# USB_USB2SS_PHY2_0F908000h register map
Vendor: Texas Instruments
Peripheral module from a debugger description file (folder AM275x).
Registers are 32-bit, read-write, reset 0x0 unless marked. A register's access mark holds for its fields unless they carry their own. Offsets are as the file gives them; lines under a group give offsets from that group; [hi:lo] are bit positions; {n}, {i} and the like mark numbered series; 'fields as' and 'values as' point back to an identical list; <NAME> marks a mode.

## usb2ss_phy2 (part 1 of 3)
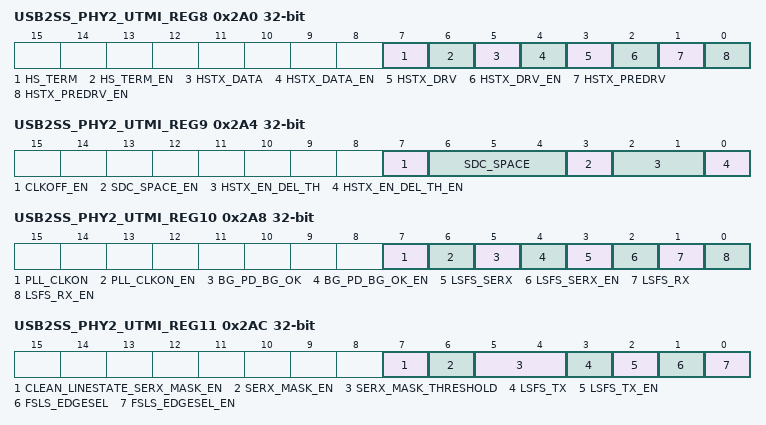
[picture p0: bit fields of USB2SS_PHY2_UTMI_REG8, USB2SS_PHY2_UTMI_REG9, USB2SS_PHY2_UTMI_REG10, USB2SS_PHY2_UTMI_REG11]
0x2A0 USB2SS_PHY2_UTMI_REG8 — This is a reserved register or field. It should not be written or read, and the value should be ignored.
  [7] HS_TERM — This is a reserved register or field. It should not be written or read, and the value should be ignored. Reset Source: usb2_sync_preset_n
  [6] HS_TERM_EN — This is a reserved register or field. It should not be written or read, and the value should be ignored. Reset Source: usb2_sync_preset_n
  [5] HSTX_DATA — This is a reserved register or field. It should not be written or read, and the value should be ignored. Reset Source: usb2_sync_preset_n
  [4] HSTX_DATA_EN — This is a reserved register or field. It should not be written or read, and the value should be ignored. Reset Source: usb2_sync_preset_n
  [3] HSTX_DRV — This is a reserved register or field. It should not be written or read, and the value should be ignored. Reset Source: usb2_sync_preset_n
  [2] HSTX_DRV_EN — This is a reserved register or field. It should not be written or read, and the value should be ignored. Reset Source: usb2_sync_preset_n
  [1] HSTX_PREDRV — This is a reserved register or field. It should not be written or read, and the value should be ignored. Reset Source: usb2_sync_preset_n
  [0] HSTX_PREDRV_EN — This is a reserved register or field. It should not be written or read, and the value should be ignored. Reset Source: usb2_sync_preset_n
0x2A4 USB2SS_PHY2_UTMI_REG9 — hs delay values
  [7] CLKOFF_EN — This is a reserved register or field. It should not be written or read, and the value should be ignored. Reset Source: usb2_sync_preset_n
  [6:4] SDC_SPACE — 000- The time between successive resistor calibration is 0ms, 001- The time between successive resistor calibration is 500ms, 010- The time between successive resistor calibration is 1000ms, 011- The time between successive resistor calibration is1500ms, 100- The time between successive resistor calibration is 2000ms, 101- The time between successive resistor calibration is 2500ms, 110- The time between successive resistor calibration is 3000ms, 111- The time between successive resistor calibration is 3500ms. Reset Source: usb2_sync_preset_n
  [3] SDC_SPACE_EN — 0- The time between successive resistor calibration taken as 1s by default, 1- The time between successive resistor calibration taken from UTMI_REG9[6:4]. Reset Source: usb2_sync_preset_n
  [2:1] HSTX_EN_DEL_TH — This is a reserved register or field. It should not be written or read, and the value should be ignored. Reset Source: usb2_sync_preset_n
  [0] HSTX_EN_DEL_TH_EN — This is a reserved register or field. It should not be written or read, and the value should be ignored. Reset Source: usb2_sync_preset_n
0x2A8 USB2SS_PHY2_UTMI_REG10 — This is a reserved register or field. It should not be written or read, and the value should be ignored.
  [7] PLL_CLKON — This is a reserved register or field. It should not be written or read, and the value should be ignored. Reset Source: usb2_sync_preset_n
  [6] PLL_CLKON_EN — This is a reserved register or field. It should not be written or read, and the value should be ignored. Reset Source: usb2_sync_preset_n
  [5] BG_PD_BG_OK — This is a reserved register or field. It should not be written or read, and the value should be ignored. Reset Source: usb2_sync_preset_n
  [4] BG_PD_BG_OK_EN — This is a reserved register or field. It should not be written or read, and the value should be ignored. Reset Source: usb2_sync_preset_n
  [3] LSFS_SERX — This is a reserved register or field. It should not be written or read, and the value should be ignored. Reset Source: usb2_sync_preset_n
  [2] LSFS_SERX_EN — This is a reserved register or field. It should not be written or read, and the value should be ignored. Reset Source: usb2_sync_preset_n
  [1] LSFS_RX — This is a reserved register or field. It should not be written or read, and the value should be ignored. Reset Source: usb2_sync_preset_n
  [0] LSFS_RX_EN — This is a reserved register or field. It should not be written or read, and the value should be ignored. Reset Source: usb2_sync_preset_n
0x2AC USB2SS_PHY2_UTMI_REG11 — This is a reserved register or field. It should not be written or read, and the value should be ignored.
  [7] CLEAN_LINESTATE_SERX_MASK_EN — This is a reserved register or field. It should not be written or read, and the value should be ignored. Reset Source: usb2_sync_preset_n
  [6] SERX_MASK_EN — This is a reserved register or field. It should not be written or read, and the value should be ignored. Reset Source: usb2_sync_preset_n
  [5:4] SERX_MASK_THRESHOLD — This is a reserved register or field. It should not be written or read, and the value should be ignored. Reset Source: usb2_sync_preset_n
  [3] LSFS_TX — This is a reserved register or field. It should not be written or read, and the value should be ignored. Reset Source: usb2_sync_preset_n
  [2] LSFS_TX_EN — This is a reserved register or field. It should not be written or read, and the value should be ignored. Reset Source: usb2_sync_preset_n
  [1] FSLS_EDGESEL — This is a reserved register or field. It should not be written or read, and the value should be ignored. Reset Source: usb2_sync_preset_n
  [0] FSLS_EDGESEL_EN — This is a reserved register or field. It should not be written or read, and the value should be ignored. Reset Source: usb2_sync_preset_n
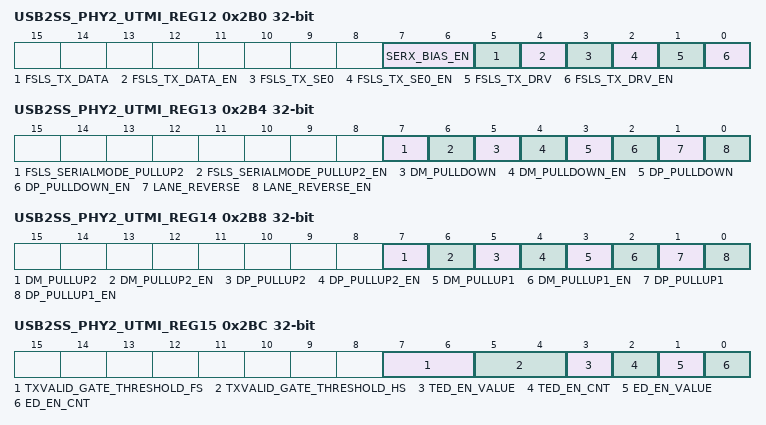
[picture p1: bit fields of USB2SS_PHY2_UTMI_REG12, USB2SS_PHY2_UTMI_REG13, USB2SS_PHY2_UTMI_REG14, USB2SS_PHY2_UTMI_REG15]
0x2B0 USB2SS_PHY2_UTMI_REG12 — This is a reserved register or field. It should not be written or read, and the value should be ignored.
  [7:6] SERX_BIAS_EN — This is a reserved register or field. It should not be written or read, and the value should be ignored. Reset Source: usb2_sync_preset_n
  [5] FSLS_TX_DATA — This is a reserved register or field. It should not be written or read, and the value should be ignored. Reset Source: usb2_sync_preset_n
  [4] FSLS_TX_DATA_EN — This is a reserved register or field. It should not be written or read, and the value should be ignored. Reset Source: usb2_sync_preset_n
  [3] FSLS_TX_SE0 — This is a reserved register or field. It should not be written or read, and the value should be ignored. Reset Source: usb2_sync_preset_n
  [2] FSLS_TX_SE0_EN — This is a reserved register or field. It should not be written or read, and the value should be ignored. Reset Source: usb2_sync_preset_n
  [1] FSLS_TX_DRV — This is a reserved register or field. It should not be written or read, and the value should be ignored. Reset Source: usb2_sync_preset_n
  [0] FSLS_TX_DRV_EN — This is a reserved register or field. It should not be written or read, and the value should be ignored. Reset Source: usb2_sync_preset_n
0x2B4 USB2SS_PHY2_UTMI_REG13 — serial mode
  [7] FSLS_SERIALMODE_PULLUP2 — This is a reserved register or field. It should not be written or read, and the value should be ignored. Reset Source: usb2_sync_preset_n
  [6] FSLS_SERIALMODE_PULLUP2_EN — This is a reserved register or field. It should not be written or read, and the value should be ignored. Reset Source: usb2_sync_preset_n
  [5] DM_PULLDOWN — This is a reserved register or field. It should not be written or read, and the value should be ignored. Reset Source: usb2_sync_preset_n
  [4] DM_PULLDOWN_EN — This is a reserved register or field. It should not be written or read, and the value should be ignored. Reset Source: usb2_sync_preset_n
  [3] DP_PULLDOWN — This is a reserved register or field. It should not be written or read, and the value should be ignored. Reset Source: usb2_sync_preset_n
  [2] DP_PULLDOWN_EN — This is a reserved register or field. It should not be written or read, and the value should be ignored. Reset Source: usb2_sync_preset_n
  [1] LANE_REVERSE — 0- Polarity inversion of DP/DM is not done, 1- Polarity inversion of DP/DM is done Reset Source: usb2_sync_preset_n
  [0] LANE_REVERSE_EN — 0- Lane Reverse Value is taken from primary input portlane_reverse, 1- Lane Reverse Value taken from UTMI_REG13[1] Reset Source: usb2_sync_preset_n
0x2B8 USB2SS_PHY2_UTMI_REG14 — This is a reserved register or field. It should not be written or read, and the value should be ignored.
  [7] DM_PULLUP2 — This is a reserved register or field. It should not be written or read, and the value should be ignored. Reset Source: usb2_sync_preset_n
  [6] DM_PULLUP2_EN — This is a reserved register or field. It should not be written or read, and the value should be ignored. Reset Source: usb2_sync_preset_n
  [5] DP_PULLUP2 — This is a reserved register or field. It should not be written or read, and the value should be ignored. Reset Source: usb2_sync_preset_n
  [4] DP_PULLUP2_EN — This is a reserved register or field. It should not be written or read, and the value should be ignored. Reset Source: usb2_sync_preset_n
  [3] DM_PULLUP1 — This is a reserved register or field. It should not be written or read, and the value should be ignored. Reset Source: usb2_sync_preset_n
  [2] DM_PULLUP1_EN — This is a reserved register or field. It should not be written or read, and the value should be ignored. Reset Source: usb2_sync_preset_n
  [1] DP_PULLUP1 — This is a reserved register or field. It should not be written or read, and the value should be ignored. Reset Source: usb2_sync_preset_n
  [0] DP_PULLUP1_EN — This is a reserved register or field. It should not be written or read, and the value should be ignored. Reset Source: usb2_sync_preset_n
0x2BC USB2SS_PHY2_UTMI_REG15 — This is a reserved register or field. It should not be written or read, and the value should be ignored.
  [7:6] TXVALID_GATE_THRESHOLD_FS — This is a reserved register or field. It should not be written or read, and the value should be ignored. Reset Source: usb2_sync_preset_n
  [5:4] TXVALID_GATE_THRESHOLD_HS — This is a reserved register or field. It should not be written or read, and the value should be ignored. Reset Source: usb2_sync_preset_n
  [3] TED_EN_VALUE — This is a reserved register or field. It should not be written or read, and the value should be ignored. Reset Source: usb2_sync_preset_n
  [2] TED_EN_CNT — This is a reserved register or field. It should not be written or read, and the value should be ignored. Reset Source: usb2_sync_preset_n
  [1] ED_EN_VALUE — This is a reserved register or field. It should not be written or read, and the value should be ignored. Reset Source: usb2_sync_preset_n
  [0] ED_EN_CNT — This is a reserved register or field. It should not be written or read, and the value should be ignored. Reset Source: usb2_sync_preset_n
0x2C0 USB2SS_PHY2_UTMI_REG16 (reset mask 0xFF) — This is a reserved register or field. It should not be written or read, and the value should be ignored.
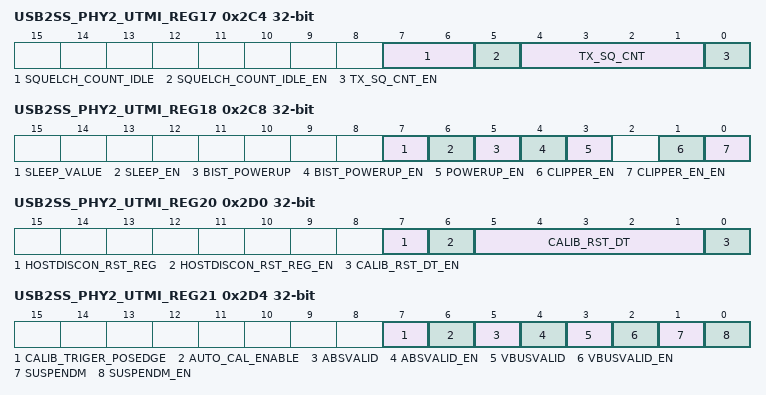
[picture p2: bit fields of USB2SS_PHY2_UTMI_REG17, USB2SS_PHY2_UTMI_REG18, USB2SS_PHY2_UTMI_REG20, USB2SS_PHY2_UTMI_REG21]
0x2C4 USB2SS_PHY2_UTMI_REG17 — This is a reserved register or field. It should not be written or read, and the value should be ignored.
  [7:6] SQUELCH_COUNT_IDLE — This is a reserved register or field. It should not be written or read, and the value should be ignored. Reset Source: usb2_sync_preset_n
  [5] SQUELCH_COUNT_IDLE_EN — This is a reserved register or field. It should not be written or read, and the value should be ignored. Reset Source: usb2_sync_preset_n
  [4:1] TX_SQ_CNT — This is a reserved register or field. It should not be written or read, and the value should be ignored. Reset Source: usb2_sync_preset_n
  [0] TX_SQ_CNT_EN — This is a reserved register or field. It should not be written or read, and the value should be ignored. Reset Source: usb2_sync_preset_n
0x2C8 USB2SS_PHY2_UTMI_REG18 — This is a reserved register or field. It should not be written or read, and the value should be ignored.
  [7] SLEEP_VALUE — This is a reserved register or field. It should not be written or read, and the value should be ignored. Reset Source: usb2_sync_preset_n
  [6] SLEEP_EN — This is a reserved register or field. It should not be written or read, and the value should be ignored. Reset Source: usb2_sync_preset_n
  [5] BIST_POWERUP — This is a reserved register or field. It should not be written or read, and the value should be ignored. Reset Source: usb2_sync_preset_n
  [4] BIST_POWERUP_EN — This is a reserved register or field. It should not be written or read, and the value should be ignored. Reset Source: usb2_sync_preset_n
  [3] POWERUP_EN — This is a reserved register or field. It should not be written or read, and the value should be ignored. Reset Source: usb2_sync_preset_n
  [1] CLIPPER_EN — This is a reserved register or field. It should not be written or read, and the value should be ignored. Reset Source: usb2_sync_preset_n
  [0] CLIPPER_EN_EN — This is a reserved register or field. It should not be written or read, and the value should be ignored. Reset Source: usb2_sync_preset_n
0x2CC USB2SS_PHY2_UTMI_REG19 — This is a reserved register or field. It should not be written or read, and the value should be ignored.
  [0] TED_SW_EN — This is a reserved register or field. It should not be written or read, and the value should be ignored. Reset Source: usb2_sync_preset_n
0x2D0 USB2SS_PHY2_UTMI_REG20 — This is a reserved register or field. It should not be written or read, and the value should be ignored.
  [7] HOSTDISCON_RST_REG — This is a reserved register or field. It should not be written or read, and the value should be ignored. Reset Source: usb2_sync_preset_n
  [6] HOSTDISCON_RST_REG_EN — This is a reserved register or field. It should not be written or read, and the value should be ignored. Reset Source: usb2_sync_preset_n
  [5:1] CALIB_RST_DT — This is a reserved register or field. It should not be written or read, and the value should be ignored. Reset Source: usb2_sync_preset_n
  [0] CALIB_RST_DT_EN — This is a reserved register or field. It should not be written or read, and the value should be ignored. Reset Source: usb2_sync_preset_n
0x2D4 USB2SS_PHY2_UTMI_REG21 — Register UTMI_REG21
  [7] CALIB_TRIGER_POSEDGE — This is a reserved register or field. It should not be written or read, and the value should be ignored. Reset Source: usb2_sync_preset_n
  [6] AUTO_CAL_ENABLE — 0- Dynamic resistor calibration is disabled, 1- Dynamic resistor calibration is enabled Reset Source: usb2_sync_preset_n
  [5] ABSVALID — This is a reserved register or field. It should not be written or read, and the value should be ignored. Reset Source: usb2_sync_preset_n
  [4] ABSVALID_EN — This is a reserved register or field. It should not be written or read, and the value should be ignored. Reset Source: usb2_sync_preset_n
  [3] VBUSVALID — This is a reserved register or field. It should not be written or read, and the value should be ignored. Reset Source: usb2_sync_preset_n
  [2] VBUSVALID_EN — This is a reserved register or field. It should not be written or read, and the value should be ignored. Reset Source: usb2_sync_preset_n
  [1] SUSPENDM — This is a reserved register or field. It should not be written or read, and the value should be ignored. Reset Source: usb2_sync_preset_n
  [0] SUSPENDM_EN — This is a reserved register or field. It should not be written or read, and the value should be ignored. Reset Source: usb2_sync_preset_n
0x2D8 USB2SS_PHY2_UTMI_REG22 — This is a reserved register or field. It should not be written or read, and the value should be ignored.
  [7:0] BCCALIB_OFFSET — This is a reserved register or field. It should not be written or read, and the value should be ignored. Reset Source: usb2_sync_preset_n
0x2DC USB2SS_PHY2_UTMI_REG23 — hscalib code offset
  [7:0] HSCALIB_OFFSET — Bit 0= 0- Final resistor calibration code going to HSTX is not offsetted, 1- Offset given by bits [6:2] is considered for computation of final resistor code going to HSTX. Bit 1= 0- ADD the offset given in bits [6:2] to the resistor calibration code before giving the code to HSTX, 1- Subtract the offset given in bits [6:2] from the reistor calibration code before giving code to HSTX. Bits 6:2= 00000 Programmable offset value for hs resistor calib code -HS OFFSET. Bit 7= reserved Reset Source: usb2_sync_preset_n
0x2E0 USB2SS_PHY2_UTMI_REG24 — fscalib code offset
  [7:0] FSCALIB_OFFSET — Bit 0= 0- Final resistor calibration code going to FSTX is not offsetted, 1- Offset given by bits [6:2] is used for computation of final resistor code going to FSTX. Bit 1= 0- ADD the offset given in bits [6:2] to the Resistor calibration code before giving the code to FSTX, 1- Subtract the offset given in bits [6:2] from the Resistor calibration code before giving code to FSTX. Bits 6:2= 00000 Programmable offset value for fs resistor calib code - FS OFFSET. Bit 7= reserved. Reset Source: usb2_sync_preset_n
0x2E4 USB2SS_PHY2_UTMI_REG25 — This is a reserved register or field. It should not be written or read, and the value should be ignored.
  [6:0] HSCALIB — This is a reserved register or field. It should not be written or read, and the value should be ignored. Reset Source: usb2_sync_preset_n
0x2E8 USB2SS_PHY2_UTMI_REG26 — This is a reserved register or field. It should not be written or read, and the value should be ignored.
  [6:0] FSCALIB — This is a reserved register or field. It should not be written or read, and the value should be ignored. Reset Source: usb2_sync_preset_n
0x2EC USB2SS_PHY2_UTMI_REG27 — This is a reserved register or field. It should not be written or read, and the value should be ignored.
  [6:0] BCCALIB — This is a reserved register or field. It should not be written or read, and the value should be ignored. Reset Source: usb2_sync_preset_n
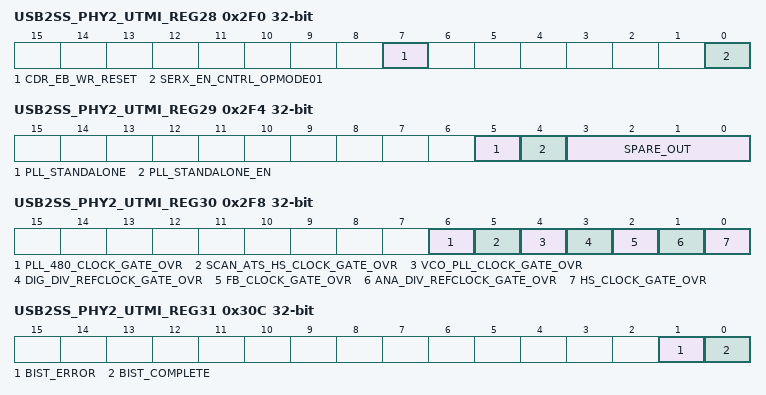
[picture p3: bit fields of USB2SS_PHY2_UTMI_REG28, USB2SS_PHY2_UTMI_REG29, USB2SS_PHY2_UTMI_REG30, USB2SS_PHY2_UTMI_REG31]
0x2F0 USB2SS_PHY2_UTMI_REG28 — This is a reserved register or field. It should not be written or read, and the value should be ignored.
  [7] CDR_EB_WR_RESET — This is a reserved register or field. It should not be written or read, and the value should be ignored. Reset Source: usb2_sync_preset_n
  [0] SERX_EN_CNTRL_OPMODE01 — This is a reserved register or field. It should not be written or read, and the value should be ignored. Reset Source: usb2_sync_preset_n
0x2F4 USB2SS_PHY2_UTMI_REG29 — This is a reserved register or field. It should not be written or read, and the value should be ignored.
  [5] PLL_STANDALONE — This is a reserved register or field. It should not be written or read, and the value should be ignored. Reset Source: usb2_sync_preset_n
  [4] PLL_STANDALONE_EN — This is a reserved register or field. It should not be written or read, and the value should be ignored. Reset Source: usb2_sync_preset_n
  [3:0] SPARE_OUT — This is a reserved register or field. It should not be written or read, and the value should be ignored. Reset Source: usb2_sync_preset_n
0x2F8 USB2SS_PHY2_UTMI_REG30 — This is a reserved register or field. It should not be written or read, and the value should be ignored.
  [6] PLL_480_CLOCK_GATE_OVR — This is a reserved register or field. It should not be written or read, and the value should be ignored. Reset Source: usb2_sync_preset_n
  [5] SCAN_ATS_HS_CLOCK_GATE_OVR — This is a reserved register or field. It should not be written or read, and the value should be ignored. Reset Source: usb2_sync_preset_n
  [4] VCO_PLL_CLOCK_GATE_OVR — This is a reserved register or field. It should not be written or read, and the value should be ignored. Reset Source: usb2_sync_preset_n
  [3] DIG_DIV_REFCLOCK_GATE_OVR — This is a reserved register or field. It should not be written or read, and the value should be ignored. Reset Source: usb2_sync_preset_n
  [2] FB_CLOCK_GATE_OVR — This is a reserved register or field. It should not be written or read, and the value should be ignored. Reset Source: usb2_sync_preset_n
  [1] ANA_DIV_REFCLOCK_GATE_OVR — This is a reserved register or field. It should not be written or read, and the value should be ignored. Reset Source: usb2_sync_preset_n
  [0] HS_CLOCK_GATE_OVR — This is a reserved register or field. It should not be written or read, and the value should be ignored. Reset Source: usb2_sync_preset_n
{0x2FC+4i} USB2SS_PHY2_UTMI_UNUSED_REG{i} (reset mask 0xFF) (i=0..3) — unused
0x30C USB2SS_PHY2_UTMI_REG31 ro — bist
  [1] BIST_ERROR — 0- BIST resulted in no Error, 1- BIST resulted in Error Reset Source: usb2_sync_preset_n
  [0] BIST_COMPLETE — 0- BIST is Not complete, 1- BIST is Complete Reset Source: usb2_sync_preset_n
0x310 USB2SS_PHY2_UTMI_REG32 ro — bist error count
  [7:0] BIST_ERR_COUNT — 00000000 Number of bytes that resulted in error while running BIST Reset Source: usb2_sync_preset_n
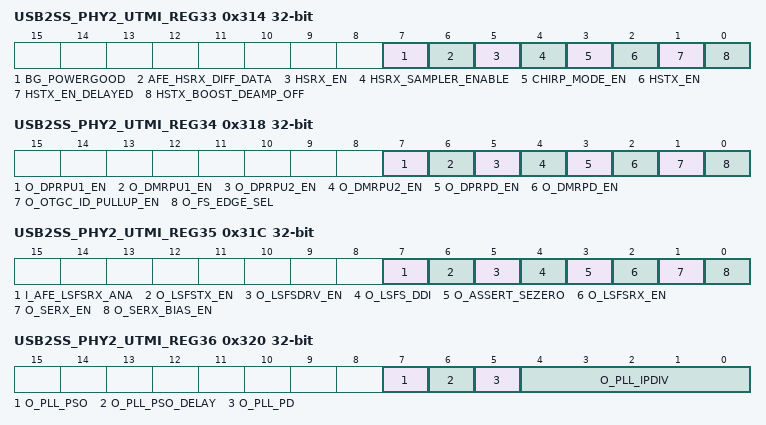
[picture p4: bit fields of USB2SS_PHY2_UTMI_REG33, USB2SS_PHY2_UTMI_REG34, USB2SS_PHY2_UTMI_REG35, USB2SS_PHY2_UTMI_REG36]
0x314 USB2SS_PHY2_UTMI_REG33 ro — This is a reserved register or field. It should not be written or read, and the value should be ignored.
  [7] BG_POWERGOOD — This is a reserved register or field. It should not be written or read, and the value should be ignored. Reset Source: usb2_sync_preset_n
  [6] AFE_HSRX_DIFF_DATA — This is a reserved register or field. It should not be written or read, and the value should be ignored. Reset Source: usb2_sync_preset_n
  [5] HSRX_EN — This is a reserved register or field. It should not be written or read, and the value should be ignored. Reset Source: usb2_sync_preset_n
  [4] HSRX_SAMPLER_ENABLE — This is a reserved register or field. It should not be written or read, and the value should be ignored. Reset Source: usb2_sync_preset_n
  [3] CHIRP_MODE_EN — This is a reserved register or field. It should not be written or read, and the value should be ignored. Reset Source: usb2_sync_preset_n
  [2] HSTX_EN — This is a reserved register or field. It should not be written or read, and the value should be ignored. Reset Source: usb2_sync_preset_n
  [1] HSTX_EN_DELAYED — This is a reserved register or field. It should not be written or read, and the value should be ignored. Reset Source: usb2_sync_preset_n
  [0] HSTX_BOOST_DEAMP_OFF — This is a reserved register or field. It should not be written or read, and the value should be ignored. Reset Source: usb2_sync_preset_n
0x318 USB2SS_PHY2_UTMI_REG34 ro — This is a reserved register or field. It should not be written or read, and the value should be ignored.
  [7] O_DPRPU1_EN — This is a reserved register or field. It should not be written or read, and the value should be ignored. Reset Source: usb2_sync_preset_n
  [6] O_DMRPU1_EN — This is a reserved register or field. It should not be written or read, and the value should be ignored. Reset Source: usb2_sync_preset_n
  [5] O_DPRPU2_EN — This is a reserved register or field. It should not be written or read, and the value should be ignored. Reset Source: usb2_sync_preset_n
  [4] O_DMRPU2_EN — This is a reserved register or field. It should not be written or read, and the value should be ignored. Reset Source: usb2_sync_preset_n
  [3] O_DPRPD_EN — This is a reserved register or field. It should not be written or read, and the value should be ignored. Reset Source: usb2_sync_preset_n
  [2] O_DMRPD_EN — This is a reserved register or field. It should not be written or read, and the value should be ignored. Reset Source: usb2_sync_preset_n
  [1] O_OTGC_ID_PULLUP_EN — This is a reserved register or field. It should not be written or read, and the value should be ignored. Reset Source: usb2_sync_preset_n
  [0] O_FS_EDGE_SEL — This is a reserved register or field. It should not be written or read, and the value should be ignored. Reset Source: usb2_sync_preset_n
0x31C USB2SS_PHY2_UTMI_REG35 ro — This is a reserved register or field. It should not be written or read, and the value should be ignored.
  [7] I_AFE_LSFSRX_ANA — This is a reserved register or field. It should not be written or read, and the value should be ignored. Reset Source: usb2_sync_preset_n
  [6] O_LSFSTX_EN — This is a reserved register or field. It should not be written or read, and the value should be ignored. Reset Source: usb2_sync_preset_n
  [5] O_LSFSDRV_EN — This is a reserved register or field. It should not be written or read, and the value should be ignored. Reset Source: usb2_sync_preset_n
  [4] O_LSFS_DDI — This is a reserved register or field. It should not be written or read, and the value should be ignored. Reset Source: usb2_sync_preset_n
  [3] O_ASSERT_SEZERO — This is a reserved register or field. It should not be written or read, and the value should be ignored. Reset Source: usb2_sync_preset_n
  [2] O_LSFSRX_EN — This is a reserved register or field. It should not be written or read, and the value should be ignored. Reset Source: usb2_sync_preset_n
  [1] O_SERX_EN — This is a reserved register or field. It should not be written or read, and the value should be ignored. Reset Source: usb2_sync_preset_n
  [0] O_SERX_BIAS_EN — This is a reserved register or field. It should not be written or read, and the value should be ignored. Reset Source: usb2_sync_preset_n
0x320 USB2SS_PHY2_UTMI_REG36 ro — This is a reserved register or field. It should not be written or read, and the value should be ignored.
  [7] O_PLL_PSO — This is a reserved register or field. It should not be written or read, and the value should be ignored. Reset Source: usb2_sync_preset_n
  [6] O_PLL_PSO_DELAY — This is a reserved register or field. It should not be written or read, and the value should be ignored. Reset Source: usb2_sync_preset_n
  [5] O_PLL_PD — This is a reserved register or field. It should not be written or read, and the value should be ignored. Reset Source: usb2_sync_preset_n
  [4:0] O_PLL_IPDIV — This is a reserved register or field. It should not be written or read, and the value should be ignored. Reset Source: usb2_sync_preset_n
0x324 USB2SS_PHY2_UTMI_REG37 ro — This is a reserved register or field. It should not be written or read, and the value should be ignored.
  [7:0] O_PLL_FBDIV_VALUE — This is a reserved register or field. It should not be written or read, and the value should be ignored. Reset Source: usb2_sync_preset_n
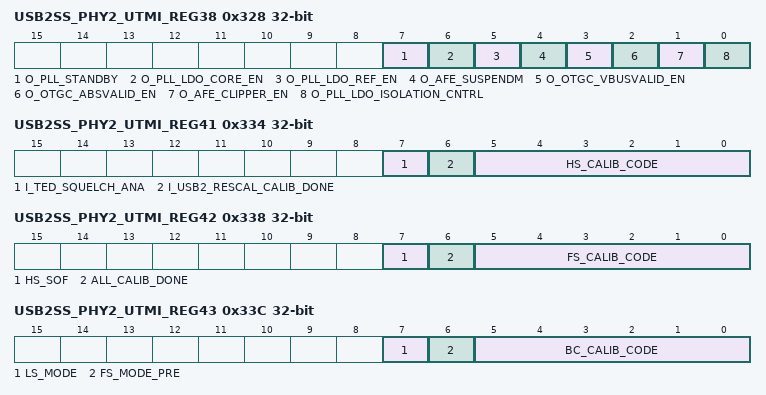
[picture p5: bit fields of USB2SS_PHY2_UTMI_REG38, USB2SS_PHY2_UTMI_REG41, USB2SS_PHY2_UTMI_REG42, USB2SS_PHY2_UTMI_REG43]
0x328 USB2SS_PHY2_UTMI_REG38 ro — This is a reserved register or field. It should not be written or read, and the value should be ignored.
  [7] O_PLL_STANDBY — This is a reserved register or field. It should not be written or read, and the value should be ignored. Reset Source: usb2_sync_preset_n
  [6] O_PLL_LDO_CORE_EN — This is a reserved register or field. It should not be written or read, and the value should be ignored. Reset Source: usb2_sync_preset_n
  [5] O_PLL_LDO_REF_EN — This is a reserved register or field. It should not be written or read, and the value should be ignored. Reset Source: usb2_sync_preset_n
  [4] O_AFE_SUSPENDM — This is a reserved register or field. It should not be written or read, and the value should be ignored. Reset Source: usb2_sync_preset_n
  [3] O_OTGC_VBUSVALID_EN — This is a reserved register or field. It should not be written or read, and the value should be ignored. Reset Source: usb2_sync_preset_n
  [2] O_OTGC_ABSVALID_EN — This is a reserved register or field. It should not be written or read, and the value should be ignored. Reset Source: usb2_sync_preset_n
  [1] O_AFE_CLIPPER_EN — This is a reserved register or field. It should not be written or read, and the value should be ignored. Reset Source: usb2_sync_preset_n
  [0] O_PLL_LDO_ISOLATION_CNTRL — This is a reserved register or field. It should not be written or read, and the value should be ignored. Reset Source: usb2_sync_preset_n
0x32C USB2SS_PHY2_UTMI_REG39 ro (reset mask 0xFF) — unused
0x330 USB2SS_PHY2_UTMI_REG40 ro (reset mask 0xFF) — unused
0x334 USB2SS_PHY2_UTMI_REG41 ro — This is a reserved register or field. It should not be written or read, and the value should be ignored.
  [7] I_TED_SQUELCH_ANA — This is a reserved register or field. It should not be written or read, and the value should be ignored. Reset Source: usb2_sync_preset_n
  [6] I_USB2_RESCAL_CALIB_DONE — This is a reserved register or field. It should not be written or read, and the value should be ignored. Reset Source: usb2_sync_preset_n
  [5:0] HS_CALIB_CODE — This is a reserved register or field. It should not be written or read, and the value should be ignored. Reset Source: usb2_sync_preset_n
0x338 USB2SS_PHY2_UTMI_REG42 ro — This is a reserved register or field. It should not be written or read, and the value should be ignored.
  [7] HS_SOF — This is a reserved register or field. It should not be written or read, and the value should be ignored. Reset Source: usb2_sync_preset_n
  [6] ALL_CALIB_DONE — This is a reserved register or field. It should not be written or read, and the value should be ignored. Reset Source: usb2_sync_preset_n
  [5:0] FS_CALIB_CODE — This is a reserved register or field. It should not be written or read, and the value should be ignored. Reset Source: usb2_sync_preset_n
0x33C USB2SS_PHY2_UTMI_REG43 ro — This is a reserved register or field. It should not be written or read, and the value should be ignored.
  [7] LS_MODE — This is a reserved register or field. It should not be written or read, and the value should be ignored. Reset Source: usb2_sync_preset_n
  [6] FS_MODE_PRE — This is a reserved register or field. It should not be written or read, and the value should be ignored. Reset Source: usb2_sync_preset_n
  [5:0] BC_CALIB_CODE — This is a reserved register or field. It should not be written or read, and the value should be ignored. Reset Source: usb2_sync_preset_n
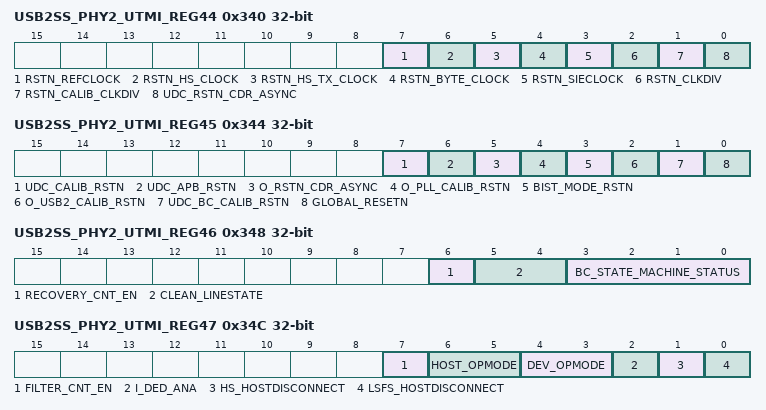
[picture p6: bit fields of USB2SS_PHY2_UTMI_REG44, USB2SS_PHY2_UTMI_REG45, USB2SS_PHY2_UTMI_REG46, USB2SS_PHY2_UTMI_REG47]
0x340 USB2SS_PHY2_UTMI_REG44 ro — This is a reserved register or field. It should not be written or read, and the value should be ignored.
  [7] RSTN_REFCLOCK — This is a reserved register or field. It should not be written or read, and the value should be ignored. Reset Source: usb2_sync_preset_n
  [6] RSTN_HS_CLOCK — This is a reserved register or field. It should not be written or read, and the value should be ignored. Reset Source: usb2_sync_preset_n
  [5] RSTN_HS_TX_CLOCK — This is a reserved register or field. It should not be written or read, and the value should be ignored. Reset Source: usb2_sync_preset_n
  [4] RSTN_BYTE_CLOCK — This is a reserved register or field. It should not be written or read, and the value should be ignored. Reset Source: usb2_sync_preset_n
  [3] RSTN_SIECLOCK — This is a reserved register or field. It should not be written or read, and the value should be ignored. Reset Source: usb2_sync_preset_n
  [2] RSTN_CLKDIV — This is a reserved register or field. It should not be written or read, and the value should be ignored. Reset Source: usb2_sync_preset_n
  [1] RSTN_CALIB_CLKDIV — This is a reserved register or field. It should not be written or read, and the value should be ignored. Reset Source: usb2_sync_preset_n
  [0] UDC_RSTN_CDR_ASYNC — This is a reserved register or field. It should not be written or read, and the value should be ignored. Reset Source: usb2_sync_preset_n
0x344 USB2SS_PHY2_UTMI_REG45 ro — This is a reserved register or field. It should not be written or read, and the value should be ignored.
  [7] UDC_CALIB_RSTN — This is a reserved register or field. It should not be written or read, and the value should be ignored. Reset Source: usb2_sync_preset_n
  [6] UDC_APB_RSTN — This is a reserved register or field. It should not be written or read, and the value should be ignored. Reset Source: usb2_sync_preset_n
  [5] O_RSTN_CDR_ASYNC — This is a reserved register or field. It should not be written or read, and the value should be ignored. Reset Source: usb2_sync_preset_n
  [4] O_PLL_CALIB_RSTN — This is a reserved register or field. It should not be written or read, and the value should be ignored. Reset Source: usb2_sync_preset_n
  [3] BIST_MODE_RSTN — This is a reserved register or field. It should not be written or read, and the value should be ignored. Reset Source: usb2_sync_preset_n
  [2] O_USB2_CALIB_RSTN — This is a reserved register or field. It should not be written or read, and the value should be ignored. Reset Source: usb2_sync_preset_n
  [1] UDC_BC_CALIB_RSTN — This is a reserved register or field. It should not be written or read, and the value should be ignored. Reset Source: usb2_sync_preset_n
  [0] GLOBAL_RESETN — This is a reserved register or field. It should not be written or read, and the value should be ignored. Reset Source: usb2_sync_preset_n
0x348 USB2SS_PHY2_UTMI_REG46 ro — This is a reserved register or field. It should not be written or read, and the value should be ignored.
  [6] RECOVERY_CNT_EN — This is a reserved register or field. It should not be written or read, and the value should be ignored. Reset Source: usb2_sync_preset_n
  [5:4] CLEAN_LINESTATE — This is a reserved register or field. It should not be written or read, and the value should be ignored. Reset Source: usb2_sync_preset_n
  [3:0] BC_STATE_MACHINE_STATUS — This is a reserved register or field. It should not be written or read, and the value should be ignored. Reset Source: usb2_sync_preset_n
0x34C USB2SS_PHY2_UTMI_REG47 ro — This is a reserved register or field. It should not be written or read, and the value should be ignored.
  [7] FILTER_CNT_EN — This is a reserved register or field. It should not be written or read, and the value should be ignored. Reset Source: usb2_sync_preset_n
  [6:5] HOST_OPMODE — This is a reserved register or field. It should not be written or read, and the value should be ignored. Reset Source: usb2_sync_preset_n
  [4:3] DEV_OPMODE — This is a reserved register or field. It should not be written or read, and the value should be ignored. Reset Source: usb2_sync_preset_n
  [2] I_DED_ANA — This is a reserved register or field. It should not be written or read, and the value should be ignored. Reset Source: usb2_sync_preset_n
  [1] HS_HOSTDISCONNECT — This is a reserved register or field. It should not be written or read, and the value should be ignored. Reset Source: usb2_sync_preset_n
  [0] LSFS_HOSTDISCONNECT — This is a reserved register or field. It should not be written or read, and the value should be ignored. Reset Source: usb2_sync_preset_n
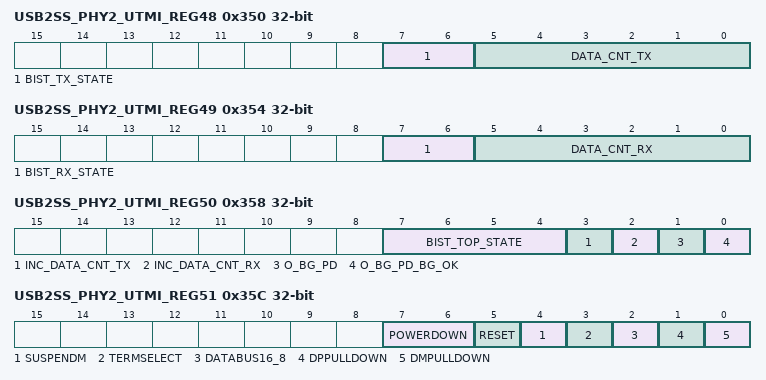
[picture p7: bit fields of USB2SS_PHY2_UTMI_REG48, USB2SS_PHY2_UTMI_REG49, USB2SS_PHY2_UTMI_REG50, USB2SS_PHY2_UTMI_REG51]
0x350 USB2SS_PHY2_UTMI_REG48 ro — This is a reserved register or field. It should not be written or read, and the value should be ignored.
  [7:6] BIST_TX_STATE — This is a reserved register or field. It should not be written or read, and the value should be ignored. Reset Source: usb2_sync_preset_n
  [5:0] DATA_CNT_TX — This is a reserved register or field. It should not be written or read, and the value should be ignored. Reset Source: usb2_sync_preset_n
0x354 USB2SS_PHY2_UTMI_REG49 ro — This is a reserved register or field. It should not be written or read, and the value should be ignored.
  [7:6] BIST_RX_STATE — This is a reserved register or field. It should not be written or read, and the value should be ignored. Reset Source: usb2_sync_preset_n
  [5:0] DATA_CNT_RX — This is a reserved register or field. It should not be written or read, and the value should be ignored. Reset Source: usb2_sync_preset_n
0x358 USB2SS_PHY2_UTMI_REG50 ro — This is a reserved register or field. It should not be written or read, and the value should be ignored.
  [7:4] BIST_TOP_STATE — This is a reserved register or field. It should not be written or read, and the value should be ignored. Reset Source: usb2_sync_preset_n
  [3] INC_DATA_CNT_TX — This is a reserved register or field. It should not be written or read, and the value should be ignored. Reset Source: usb2_sync_preset_n
  [2] INC_DATA_CNT_RX — This is a reserved register or field. It should not be written or read, and the value should be ignored. Reset Source: usb2_sync_preset_n
  [1] O_BG_PD — This is a reserved register or field. It should not be written or read, and the value should be ignored. Reset Source: usb2_sync_preset_n
  [0] O_BG_PD_BG_OK — This is a reserved register or field. It should not be written or read, and the value should be ignored. Reset Source: usb2_sync_preset_n
0x35C USB2SS_PHY2_UTMI_REG51 ro — This is a reserved register or field. It should not be written or read, and the value should be ignored.
  [7:6] POWERDOWN — This is a reserved register or field. It should not be written or read, and the value should be ignored. Reset Source: usb2_sync_preset_n
  [5] RESET — This is a reserved register or field. It should not be written or read, and the value should be ignored. Reset Source: usb2_sync_preset_n
  [4] SUSPENDM — This is a reserved register or field. It should not be written or read, and the value should be ignored. Reset Source: usb2_sync_preset_n
  [3] TERMSELECT — This is a reserved register or field. It should not be written or read, and the value should be ignored. Reset Source: usb2_sync_preset_n
  [2] DATABUS16_8 — This is a reserved register or field. It should not be written or read, and the value should be ignored. Reset Source: usb2_sync_preset_n
  [1] DPPULLDOWN — This is a reserved register or field. It should not be written or read, and the value should be ignored. Reset Source: usb2_sync_preset_n
  [0] DMPULLDOWN — This is a reserved register or field. It should not be written or read, and the value should be ignored. Reset Source: usb2_sync_preset_n
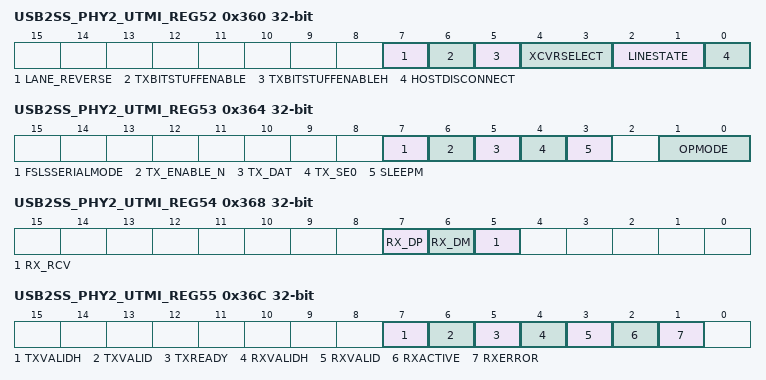
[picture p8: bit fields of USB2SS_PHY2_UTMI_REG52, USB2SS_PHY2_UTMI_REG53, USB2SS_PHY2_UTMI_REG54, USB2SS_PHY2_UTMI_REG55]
0x360 USB2SS_PHY2_UTMI_REG52 ro — This is a reserved register or field. It should not be written or read, and the value should be ignored.
  [7] LANE_REVERSE — This is a reserved register or field. It should not be written or read, and the value should be ignored. Reset Source: usb2_sync_preset_n
  [6] TXBITSTUFFENABLE — This is a reserved register or field. It should not be written or read, and the value should be ignored. Reset Source: usb2_sync_preset_n
  [5] TXBITSTUFFENABLEH — This is a reserved register or field. It should not be written or read, and the value should be ignored. Reset Source: usb2_sync_preset_n
  [4:3] XCVRSELECT — This is a reserved register or field. It should not be written or read, and the value should be ignored. Reset Source: usb2_sync_preset_n
  [2:1] LINESTATE — This is a reserved register or field. It should not be written or read, and the value should be ignored. Reset Source: usb2_sync_preset_n
  [0] HOSTDISCONNECT — This is a reserved register or field. It should not be written or read, and the value should be ignored. Reset Source: usb2_sync_preset_n
0x364 USB2SS_PHY2_UTMI_REG53 ro — This is a reserved register or field. It should not be written or read, and the value should be ignored.
  [7] FSLSSERIALMODE — This is a reserved register or field. It should not be written or read, and the value should be ignored. Reset Source: usb2_sync_preset_n
  [6] TX_ENABLE_N — This is a reserved register or field. It should not be written or read, and the value should be ignored. Reset Source: usb2_sync_preset_n
  [5] TX_DAT — This is a reserved register or field. It should not be written or read, and the value should be ignored. Reset Source: usb2_sync_preset_n
  [4] TX_SE0 — This is a reserved register or field. It should not be written or read, and the value should be ignored. Reset Source: usb2_sync_preset_n
  [3] SLEEPM — This is a reserved register or field. It should not be written or read, and the value should be ignored. Reset Source: usb2_sync_preset_n
  [1:0] OPMODE — This is a reserved register or field. It should not be written or read, and the value should be ignored. Reset Source: usb2_sync_preset_n
0x368 USB2SS_PHY2_UTMI_REG54 ro — This is a reserved register or field. It should not be written or read, and the value should be ignored.
  [7] RX_DP — This is a reserved register or field. It should not be written or read, and the value should be ignored. Reset Source: usb2_sync_preset_n
  [6] RX_DM — This is a reserved register or field. It should not be written or read, and the value should be ignored. Reset Source: usb2_sync_preset_n
  [5] RX_RCV — This is a reserved register or field. It should not be written or read, and the value should be ignored. Reset Source: usb2_sync_preset_n
0x36C USB2SS_PHY2_UTMI_REG55 ro — This is a reserved register or field. It should not be written or read, and the value should be ignored.
  [7] TXVALIDH — This is a reserved register or field. It should not be written or read, and the value should be ignored. Reset Source: usb2_sync_preset_n
  [6] TXVALID — This is a reserved register or field. It should not be written or read, and the value should be ignored. Reset Source: usb2_sync_preset_n
  [5] TXREADY — This is a reserved register or field. It should not be written or read, and the value should be ignored. Reset Source: usb2_sync_preset_n
  [4] RXVALIDH — This is a reserved register or field. It should not be written or read, and the value should be ignored. Reset Source: usb2_sync_preset_n
  [3] RXVALID — This is a reserved register or field. It should not be written or read, and the value should be ignored. Reset Source: usb2_sync_preset_n
  [2] RXACTIVE — This is a reserved register or field. It should not be written or read, and the value should be ignored. Reset Source: usb2_sync_preset_n
  [1] RXERROR — This is a reserved register or field. It should not be written or read, and the value should be ignored. Reset Source: usb2_sync_preset_n
0x370 USB2SS_PHY2_UTMI_REG56 ro — This is a reserved register or field. It should not be written or read, and the value should be ignored.
  [7:0] DATAIN_UPPER — This is a reserved register or field. It should not be written or read, and the value should be ignored. Reset Source: usb2_sync_preset_n
0x374 USB2SS_PHY2_UTMI_REG57 ro — This is a reserved register or field. It should not be written or read, and the value should be ignored.
  [7:0] DATAIN_LOWER — This is a reserved register or field. It should not be written or read, and the value should be ignored. Reset Source: usb2_sync_preset_n
0x378 USB2SS_PHY2_UTMI_REG58 ro — This is a reserved register or field. It should not be written or read, and the value should be ignored.
  [7:0] DATAOUT_UPPER — This is a reserved register or field. It should not be written or read, and the value should be ignored. Reset Source: usb2_sync_preset_n
0x37C USB2SS_PHY2_UTMI_REG59 ro — This is a reserved register or field. It should not be written or read, and the value should be ignored.
  [7:0] DATAOUT_LOWER — This is a reserved register or field. It should not be written or read, and the value should be ignored. Reset Source: usb2_sync_preset_n
0x380 USB2SS_PHY2_UTMI_UNUSED_REG6 ro (reset mask 0xFF) — UNUSED
0x384 USB2SS_PHY2_UTMI_UNUSED_REG7 ro (reset mask 0xFF) — UNUSED
